VERSION ""

NS_ :

BS_:

BU_: Steer Pedals VehicleControl

BO_ 3221225472 VECTOR__INDEPENDENT_SIG_MSG: 0 Vector__XXX
 SG_ LaneInvaded : 8|1@1+ (1,0) [0|0] "" Vector__XXX

BO_ 1 Steer: 1 Steer
 SG_ Degree : 0|8@1+ (1,0) [0|0] "" Vector__XXX

BO_ 2 Pedal: 2 Pedals
 SG_ Throttle : 8|8@1+ (1,0) [0|0] "" Vector__XXX
 SG_ Brake : 0|8@1+ (1,0) [0|0] "" Vector__XXX

BO_ 3 GearMsg: 1 VehicleControl
 SG_ Gear : 0|3@1+ (1,0) [0|0] "" Vector__XXX
 SG_ Reverse : 3|1@1+ (1,0) [0|0] "" Vector__XXX

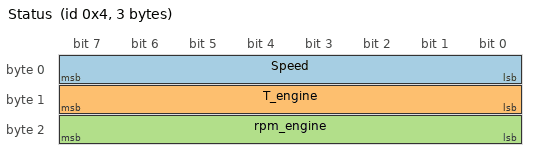
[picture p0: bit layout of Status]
BO_ 4 Status: 3 VehicleControl
 SG_ Speed : 0|8@1+ (1,0) [0|0] "" Vector__XXX
 SG_ T_engine : 8|8@1+ (1,0) [0|0] "" Vector__XXX
 SG_ rpm_engine : 16|8@1+ (1,0) [0|0] "" Vector__XXX

BO_ 5 Control_msg: 1 VehicleControl
 SG_ Th_state : 0|1@1+ (1,0) [0|0] "" Vector__XXX

BA_DEF_  "BusType" STRING ;
BA_DEF_DEF_  "BusType" "CAN";
